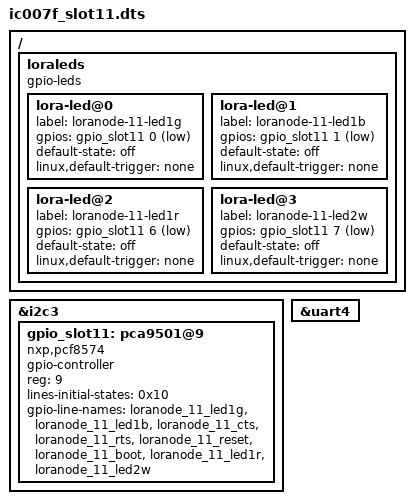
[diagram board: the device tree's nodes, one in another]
/dts-v1/;


/plugin/;

/ {
	fragment@0 {
		target = <&i2c3>;
		__overlay__ {
			#address-cells = <1>;
			#size-cells = <0>;
			gpio_slot11: pca9501@9 {
				compatible = "nxp,pcf8574";
				gpio-controller;
				#gpio-cells = <2>;
				reg = <9>;
				lines-initial-states = <0x10>;
                gpio-line-names ="loranode_11_led1g",
                "loranode_11_led1b",
                "loranode_11_cts",
                "loranode_11_rts",
                "loranode_11_reset",
                "loranode_11_boot",
                "loranode_11_led1r",
                "loranode_11_led2w";
                
			};
		};
	};

	fragment@3 {
		
		target = <&uart4>;
		__overlay__ {
			status = "okay";
		};

	};

	fragment@4 {
		target-path = "/";
		__overlay__ {
			loraleds {
				compatible = "gpio-leds";
				lora-led@0 {
					label = "loranode-11-led1g";
					gpios = <&gpio_slot11 0 1>;
					default-state = "off";
					linux,default-trigger = "none";
				};
				lora-led@1 {
					label = "loranode-11-led1b";
					gpios = <&gpio_slot11 1 1>;
					default-state = "off";
					linux,default-trigger = "none";
				};				
				lora-led@2 {
					label = "loranode-11-led1r";
					gpios = <&gpio_slot11 6 1>;
					default-state = "off";
					linux,default-trigger = "none";
				};
				lora-led@3 {
					label = "loranode-11-led2w";
					gpios = <&gpio_slot11 7 1>;
					default-state = "off";
					linux,default-trigger = "none";
				};
			};
		};
	};
};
